# STM32H7RSxx register map
File version: 0.2
CPU: CM7 r0p1, little endian, MPU, FPU, 4 interrupt priority bits
Registers are 32-bit, read-write, reset 0x0 unless marked. A register's access mark holds for its fields unless they carry their own. Offsets are from the block's base; [hi:lo] are bit positions.

## LPTIM4 — Low power timer
Base 0x58002C00
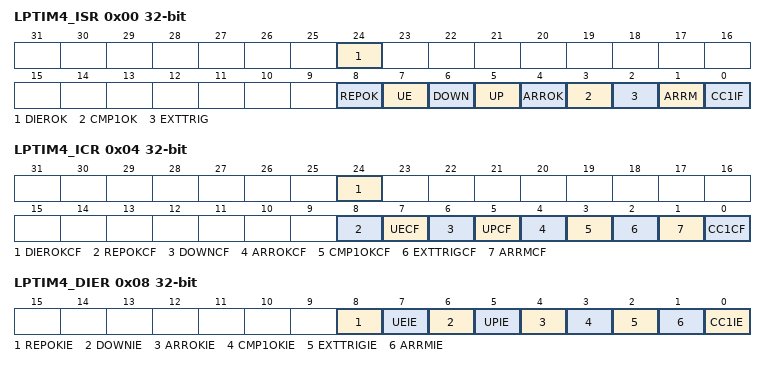
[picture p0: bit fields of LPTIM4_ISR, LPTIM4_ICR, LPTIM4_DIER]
0x00 LPTIM4_ISR ro — LPTIM4 interrupt and status register
  [24] DIEROK — Interrupt enable register update OK DIEROK is set by hardware to inform application that the APB bus write operation to the LPTIM_DIER register has been successfully completed. DIEROK flag can be cleared by writing 1 to the DIEROKCF bit in the LPTIM_ICR register.
  [8] REPOK — Repetition register update OK REPOK is set by hardware to inform application that the APB bus write operation to the LPTIM_RCR register has been successfully completed. REPOK flag can be cleared by writing 1 to the REPOKCF bit in the LPTIM_ICR register.
  [7] UE — LPTIM update event occurred UE is set by hardware to inform application that an update event was generated. UE flag can be cleared by writing 1 to the UECF bit in the LPTIM_ICR register.
  [6] DOWN — Counter direction change up to down In Encoder mode, DOWN bit is set by hardware to inform application that the counter direction has changed from up to down. DOWN flag can be cleared by writing 1 to the DOWNCF bit in the LPTIM_ICR register. Note: If the LPTIM does not support encoder mode feature, this bit is reserved. Refer to Section 26.3: LPTIM implementation.
  [5] UP — Counter direction change down to up In Encoder mode, UP bit is set by hardware to inform application that the counter direction has changed from down to up. UP flag can be cleared by writing 1 to the UPCF bit in the LPTIM_ICR register. Note: If the LPTIM does not support encoder mode feature, this bit is reserved. Refer to Section 26.3: LPTIM implementation.
  [4] ARROK — Autoreload register update OK ARROK is set by hardware to inform application that the APB bus write operation to the LPTIM_ARR register has been successfully completed. ARROK flag can be cleared by writing 1 to the ARROKCF bit in the LPTIM_ICR register.
  [3] CMP1OK — Compare register 1 update OK CMP1OK is set by hardware to inform application that the APB bus write operation to the LPTIM_CCR1 register has been successfully completed. CMP1OK flag can be cleared by writing 1 to the CMP1OKCF bit in the LPTIM_ICR register.
  [2] EXTTRIG — External trigger edge event EXTTRIG is set by hardware to inform application that a valid edge on the selected external trigger input has occurred. If the trigger is ignored because the timer has already started, then this flag is not set. EXTTRIG flag can be cleared by writing 1 to the EXTTRIGCF bit in the LPTIM_ICR register.
  [1] ARRM — Autoreload match ARRM is set by hardware to inform application that LPTIM_CNT register’s value reached the LPTIM_ARR register’s value. ARRM flag can be cleared by writing 1 to the ARRMCF bit in the LPTIM_ICR register.
  [0] CC1IF — Compare 1 interrupt flag The CC1IF flag is set by hardware to inform application that LPTIM_CNT register value matches the compare register's value. The CC1IF flag can be cleared by writing 1 to the CC1CF bit in the LPTIM_ICR register.
    0=No match; 1=The content of the counter LPTIM_CNT register value has matched the LPTIM_CCR1 register's value
0x04 LPTIM4_ICR wo — LPTIM4 interrupt clear register
  [24] DIEROKCF — Interrupt enable register update OK clear flag Writing 1 to this bit clears the DIEROK flag in the LPTIM_ISR register.
  [8] REPOKCF — Repetition register update OK clear flag Writing 1 to this bit clears the REPOK flag in the LPTIM_ISR register.
  [7] UECF — Update event clear flag Writing 1 to this bit clear the UE flag in the LPTIM_ISR register.
  [6] DOWNCF — Direction change to down clear flag Writing 1 to this bit clear the DOWN flag in the LPTIM_ISR register. Note: If the LPTIM does not support encoder mode feature, this bit is reserved. Refer to Section 26.3.
  [5] UPCF — Direction change to UP clear flag Writing 1 to this bit clear the UP flag in the LPTIM_ISR register. Note: If the LPTIM does not support encoder mode feature, this bit is reserved. Refer to Section 26.3.
  [4] ARROKCF — Autoreload register update OK clear flag Writing 1 to this bit clears the ARROK flag in the LPTIM_ISR register
  [3] CMP1OKCF — Compare register 1 update OK clear flag Writing 1 to this bit clears the CMP1OK flag in the LPTIM_ISR register.
  [2] EXTTRIGCF — External trigger valid edge clear flag Writing 1 to this bit clears the EXTTRIG flag in the LPTIM_ISR register
  [1] ARRMCF — Autoreload match clear flag Writing 1 to this bit clears the ARRM flag in the LPTIM_ISR register
  [0] CC1CF — Capture/compare 1 clear flag Writing 1 to this bit clears the CC1IF flag in the LPTIM_ISR register.
0x08 LPTIM4_DIER — LPTIM4 interrupt enable register
  [8] REPOKIE — Repetition register update OK interrupt Enable
    0=Repetition register update OK interrupt disabled; 1=Repetition register update OK interrupt enabled
  [7] UEIE — Update event interrupt enable
    0=Update event interrupt disabled; 1=Update event interrupt enabled
  [6] DOWNIE — Direction change to down Interrupt Enable Note: If the LPTIM does not support encoder mode feature, this bit is reserved. Refer to Section 26.3.
    0=DOWN interrupt disabled; 1=DOWN interrupt enabled
  [5] UPIE — Direction change to UP Interrupt Enable Note: If the LPTIM does not support encoder mode feature, this bit is reserved. Refer to Section 26.3.
    0=UP interrupt disabled; 1=UP interrupt enabled
  [4] ARROKIE — Autoreload register update OK Interrupt Enable
    0=ARROK interrupt disabled; 1=ARROK interrupt enabled
  [3] CMP1OKIE — Compare register 1 update OK interrupt enable
    0=CMPOK register 1 interrupt disabled; 1=CMPOK register 1 interrupt enabled
  [2] EXTTRIGIE — External trigger valid edge Interrupt Enable
    0=EXTTRIG interrupt disabled; 1=EXTTRIG interrupt enabled
  [1] ARRMIE — Autoreload match Interrupt Enable
    0=ARRM interrupt disabled; 1=ARRM interrupt enabled
  [0] CC1IE — Capture/compare 1 interrupt enable
    0=Capture/compare 1 interrupt disabled; 1=Capture/compare 1 interrupt enabled

## LPTIM5 — Low power timer
Base 0x58003000
Registers as LPTIM4 (with LPTIM4 read as LPTIM5).
